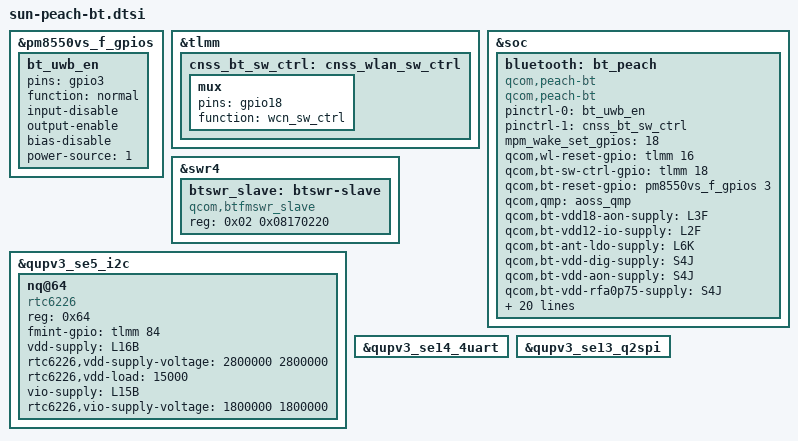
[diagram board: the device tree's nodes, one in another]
// SPDX-License-Identifier: BSD-3-Clause

/*
 * Copyright (c) 2023 Qualcomm Innovation Center, Inc. All rights reserved.
 */

#include <dt-bindings/interconnect/qcom,sun.h>

&pm8550vs_f_gpios {
	bt_uwb_en: bt_uwb_en {
		pins = "gpio3";
		function = "normal";
		input-disable;
		output-enable;
		bias-disable;
		power-source = <1>;
	};
};

&tlmm {
	cnss_bt_sw_ctrl: cnss_wlan_sw_ctrl {
		mux {
			pins = "gpio18";
			function = "wcn_sw_ctrl";
		};
	};
};

&soc {
	bluetooth: bt_peach {
			compatible = "qcom,peach-bt";
			qcom,peach-bt;
			pinctrl-names = "bt_uwb_en", "sw_ctrl";
			pinctrl-0 = <&bt_uwb_en>;
			pinctrl-1 = <&cnss_bt_sw_ctrl>;
			/* List of GPIOs to be setup for interrupt wakeup capable*/
			mpm_wake_set_gpios = <18>;
			qcom,wl-reset-gpio = <&tlmm 16 0>; /* WL_EN */
			qcom,bt-sw-ctrl-gpio = <&tlmm 18 0>; /* SW_CTRL */
			qcom,bt-reset-gpio = <&pm8550vs_f_gpios 3 0>; /* BT_EN */
			qcom,qmp = <&aoss_qmp>;

			qcom,bt-vdd18-aon-supply  = <&L3F>;   /* VDD1P8_AON */
			qcom,bt-vdd12-io-supply   = <&L2F>;   /* VDD1P2_IO */
			qcom,bt-ant-ldo-supply    = <&L6K>;   /* AV91C_VDD Extractor */
			qcom,bt-vdd-dig-supply    = <&S4J>;   /* BT CX_MX LDO */
			qcom,bt-vdd-aon-supply    = <&S4J>;   /* RFA_CMN/AON */
			qcom,bt-vdd-rfa0p75-supply = <&S4J>;  /* RFA_OP75 */
			qcom,bt-vdd-rfa1p8-supply  = <&S3G>;  /* RFA_1P8 */
			qcom,bt-vdd-rfa1p25-supply = <&S7I>; /* RFA_1P2 */

			qcom,bt-vdd18-aon-config  = <1800000 1800000 30000 1 0>;
			qcom,bt-vdd12-io-config   = <1200000 1200000 30000 1 0>;
			qcom,bt-ant-ldo-config    = <1800000 1860000 0 1 0>;
			qcom,bt-vdd-aon-config    = <876000 1000000 0 1 0>;
			qcom,bt-vdd-dig-config    = <876000 1000000 0 1 0>;
			qcom,bt-vdd-rfa0p75-config = <876000 1000000 0 1 0>;
			qcom,bt-vdd-rfa1p8-config = <1860000 2000000 0 1 0>;
			qcom,bt-vdd-rfa1p25-config  = <1312000 1340000 0 1 0>;

			qcom,pdc_init_table =
				"{class: wlan_pdc, ss: rf, res: s4j.m, enable: 1}",
				"{class: wlan_pdc, ss: rf, res: s4j.v, enable: 1}",
				"{class: wlan_pdc, ss: rf, res: s4j.v, upval: 876}",
				"{class: wlan_pdc, ss: rf, res: s4j.v, dwnval: 876}";
	};
};

&swr4 {
	btswr_slave: btswr-slave {
		compatible = "qcom,btfmswr_slave";
		reg = <0x02 0x08170220>;
	};
};

// FM changes
&qupv3_se5_i2c {
    status = "ok";
	nq@64 {
		compatible = "rtc6226";
		reg = <0x64>;
		fmint-gpio = <&tlmm 84 0>;
		vdd-supply = <&L16B>;
		rtc6226,vdd-supply-voltage = <2800000 2800000>;
		rtc6226,vdd-load = <15000>;
		vio-supply = <&L15B>;
		rtc6226,vio-supply-voltage = <1800000 1800000>;
	};
};

//uart instance
&qupv3_se14_4uart {
	status = "ok";
};

//q2spi instance
&qupv3_se13_q2spi {
	status = "ok";
};
